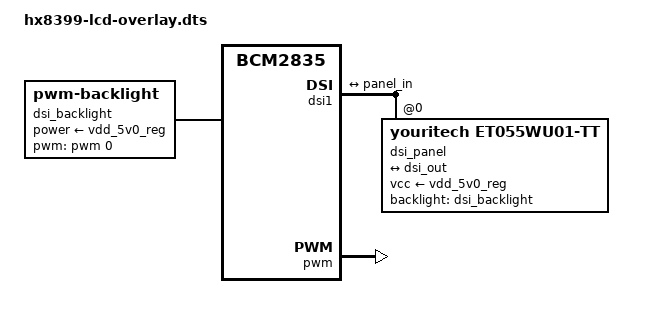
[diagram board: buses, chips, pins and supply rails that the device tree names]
/dts-v1/;
/plugin/;

/ {
	compatible = "brcm,bcm2835";

	fragment@0 {
		target = <&dsi1>;
		__overlay__ {
			#address-cells = <1>;
			#size-cells = <0>;
			status = "okay";

			port {
				dsi_out: endpoint {
					remote-endpoint = <&panel_in>;
				};
			};

			dsi_panel: dsi_panel@0 {
				compatible = "youritech,et055wu01-tt";
				reg = <0>;
				vcc-supply = <&vdd_5v0_reg>;
				backlight = <&dsi_backlight>;

				port {
					panel_in: endpoint {
						remote-endpoint = <&dsi_out>;
					};
				};
			};
		};
	};

	fragment@1 {
		target = <&gpio>;
		__overlay__ {
			pwm0_pins: pwm0_pins {
				brcm,pins = <12>;
				brcm,function = <4>; /* Alt0 */
			};
		};
	};

	fragment@2 {
		target = <&pwm>;
		__overlay__ {
			pinctrl-names = "default";
			pinctrl-0 = <&pwm0_pins>;
			assigned-clock-rates = <1000000>;
			status = "okay";
		};
	};

	fragment@3 {
		target = <&pwm>;
		__overlay__ {
			status = "okay";
		};
	};

	fragment@4 {
		target-path = "/";
		__overlay__ {
			dsi_backlight: dsi_backlight {
				compatible = "pwm-backlight";
				brightness-levels = <0 6 8 12 16 24 32 40 48 64 96 128 160 192 224 255>;
				default-brightness-level = <15>;
				pwms = <&pwm 0 200000 0>;
				power-supply = <&vdd_5v0_reg>;
				status = "okay";
			};
		 };
	};
};
